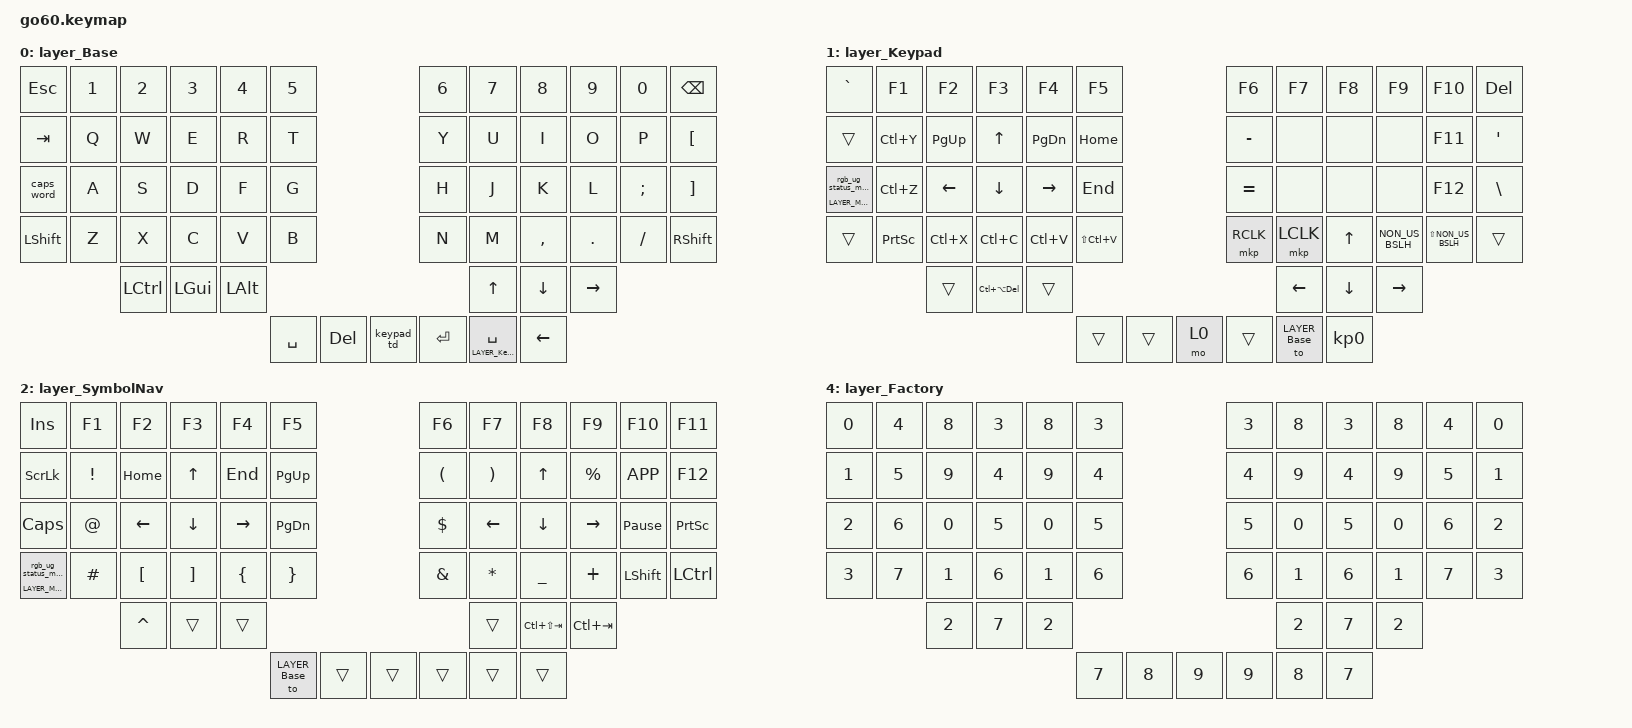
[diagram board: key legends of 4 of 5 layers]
/*
 * Copyright (c) 2020 The ZMK Contributors
 *
 * SPDX-License-Identifier: MIT
 */

#include <behaviors.dtsi>

#include <dt-bindings/zmk/bt.h>
#include <dt-bindings/zmk/ext_power.h>
#include <dt-bindings/zmk/keys.h>
#include <dt-bindings/zmk/outputs.h>
#include <dt-bindings/zmk/rgb.h>
#include <dt-bindings/zmk/input_transform.h>
#include <dt-bindings/zmk/pointing.h>

#include <input/processors.dtsi>
#include <zephyr/dt-bindings/input/input-event-codes.h>

// layers
#define LAYER_Base 0
#define LAYER_Keypad 1
#define LAYER_SymbolNav 2
#define LAYER_Magic 3
#define LAYER_Factory 4



/* Key positions */

#define POS_LH_C6R1 0
#define POS_LH_C5R1 1
#define POS_LH_C4R1 2
#define POS_LH_C3R1 3
#define POS_LH_C2R1 4
#define POS_LH_C1R1 5
#define POS_RH_C1R1 6
#define POS_RH_C2R1 7
#define POS_RH_C3R1 8
#define POS_RH_C4R1 9
#define POS_RH_C5R1 10
#define POS_RH_C6R1 11
#define POS_LH_C6R2 12
#define POS_LH_C5R2 13
#define POS_LH_C4R2 14
#define POS_LH_C3R2 15
#define POS_LH_C2R2 16
#define POS_LH_C1R2 17
#define POS_RH_C1R2 18
#define POS_RH_C2R2 19
#define POS_RH_C3R2 20
#define POS_RH_C4R2 21
#define POS_RH_C5R2 22
#define POS_RH_C6R2 23
#define POS_LH_C6R3 24
#define POS_LH_C5R3 25
#define POS_LH_C4R3 26
#define POS_LH_C3R3 27
#define POS_LH_C2R3 28
#define POS_LH_C1R3 29
#define POS_RH_C1R3 30
#define POS_RH_C2R3 31
#define POS_RH_C3R3 32
#define POS_RH_C4R3 33
#define POS_RH_C5R3 34
#define POS_RH_C6R3 35
#define POS_LH_C6R4 36
#define POS_LH_C5R4 37
#define POS_LH_C4R4 38
#define POS_LH_C3R4 39
#define POS_LH_C2R4 40
#define POS_LH_C1R4 41
#define POS_RH_C1R4 42
#define POS_RH_C2R4 43
#define POS_RH_C3R4 44
#define POS_RH_C4R4 45
#define POS_RH_C5R4 46
#define POS_RH_C6R4 47
#define POS_LH_C4R5 48
#define POS_LH_C3R5 49
#define POS_LH_C2R5 50
#define POS_RH_C2R5 51
#define POS_RH_C3R5 52
#define POS_RH_C4R5 53
#define POS_LH_T1 54
#define POS_LH_T2 55
#define POS_LH_T3 56
#define POS_RH_T3 57
#define POS_RH_T2 58
#define POS_RH_T1 59


#define LEFT_HAND_KEYS \
  POS_LH_C1R1 POS_LH_C2R1 POS_LH_C3R1 POS_LH_C4R1 POS_LH_C5R1 POS_LH_C6R1 \
  POS_LH_C1R2 POS_LH_C2R2 POS_LH_C3R2 POS_LH_C4R2 POS_LH_C5R2 POS_LH_C6R2 \
  POS_LH_C1R3 POS_LH_C2R3 POS_LH_C3R3 POS_LH_C4R3 POS_LH_C5R3 POS_LH_C6R3 \
  POS_LH_C1R4 POS_LH_C2R4 POS_LH_C3R4 POS_LH_C4R4 POS_LH_C5R4 POS_LH_C6R4 \
              POS_LH_C2R5 POS_LH_C3R5 POS_LH_C4R5

#define RIGHT_HAND_KEYS \
  POS_RH_C1R1 POS_RH_C2R1 POS_RH_C3R1 POS_RH_C4R1 POS_RH_C5R1 POS_RH_C6R1 \
  POS_RH_C1R2 POS_RH_C2R2 POS_RH_C3R2 POS_RH_C4R2 POS_RH_C5R2 POS_RH_C6R2 \
  POS_RH_C1R3 POS_RH_C2R3 POS_RH_C3R3 POS_RH_C4R3 POS_RH_C5R3 POS_RH_C6R3 \
  POS_RH_C1R4 POS_RH_C2R4 POS_RH_C3R4 POS_RH_C4R4 POS_RH_C5R4 POS_RH_C6R4 \
              POS_RH_C2R5 POS_RH_C3R5 POS_RH_C4R5

#define THUMB_KEYS \
  POS_LH_T1 POS_LH_T2 POS_LH_T3 \
  POS_RH_T1 POS_RH_T2 POS_RH_T3

/* Environment and metadata defines */
#define KB_TYPE_GLOVE_80 1
#define KB_TYPE_GO_60    2

#define KB_TYPE          KB_TYPE_GO_60
#define EDITOR_LAYOUT_OS 'W'
#define EDITOR_HOST_OS   'W'

/* To deal with the situation where there is no Lower layer, to keep &lower happy */
#ifndef LAYER_Lower
#define LAYER_Lower 0
#endif

/ {
    input_processors {
        zip_click_to_right_click_mapper: zip_click_to_right_click_mapper {
            compatible = "zmk,input-processor-code-mapper";
            #input-processor-cells = <0>;
            type = <INPUT_EV_KEY>;
            map = <INPUT_BTN_0 INPUT_BTN_1>;
        };
    };

    behaviors {
        magic: magic {
            compatible = "zmk,behavior-hold-tap";
            #binding-cells = <2>;
            flavor = "tap-preferred";
            tapping-term-ms = <200>;
            bindings = <&mo>, <&rgb_ug_status_macro>;
        };

        keypad_td: keypad_td {
            compatible = "zmk,behavior-tap-dance";
            #binding-cells = <0>;
            tapping-term-ms = <200>;
            bindings = <&mo LAYER_Keypad>, <&to LAYER_Keypad>;
        };

        symbol_nav_td: symbol_nav_td {
            compatible = "zmk,behavior-tap-dance";
            #binding-cells = <0>;
            tapping-term-ms = <200>;
            bindings = <&mo LAYER_SymbolNav>, <&to LAYER_SymbolNav>;
        };

        bt_0: bt_0 {
            compatible = "zmk,behavior-tap-dance";
            #binding-cells = <0>;
            tapping-term-ms = <200>;
            bindings = <&bt_select_0>, <&bt BT_DISC 0>;
        };
        bt_1: bt_1 {
            compatible = "zmk,behavior-tap-dance";
            #binding-cells = <0>;
            tapping-term-ms = <200>;
            bindings = <&bt_select_1>, <&bt BT_DISC 1>;
        };
        bt_2: bt_2 {
            compatible = "zmk,behavior-tap-dance";
            #binding-cells = <0>;
            tapping-term-ms = <200>;
            bindings = <&bt_select_2>, <&bt BT_DISC 2>;
        };
        bt_3: bt_3 {
            compatible = "zmk,behavior-tap-dance";
            #binding-cells = <0>;
            tapping-term-ms = <200>;
            bindings = <&bt_select_3>, <&bt BT_DISC 3>;
        };
    };

    macros {
        rgb_ug_status_macro: rgb_ug_status_macro {
            compatible = "zmk,behavior-macro";
            #binding-cells = <0>;
            bindings = <&rgb_ug RGB_STATUS>;
        };

        bt_select_0: bt_select_0 {
            compatible = "zmk,behavior-macro";
            #binding-cells = <0>;
            bindings
                = <&out OUT_BLE>,
                  <&bt BT_SEL 0>;
        };
        bt_select_1: bt_select_1 {
            compatible = "zmk,behavior-macro";
            #binding-cells = <0>;
            bindings
                = <&out OUT_BLE>,
                  <&bt BT_SEL 1>;
        };
        bt_select_2: bt_select_2 {
            compatible = "zmk,behavior-macro";
            #binding-cells = <0>;
            bindings
                = <&out OUT_BLE>,
                  <&bt BT_SEL 2>;
        };
        bt_select_3: bt_select_3 {
            compatible = "zmk,behavior-macro";
            #binding-cells = <0>;
            bindings
                = <&out OUT_BLE>,
                  <&bt BT_SEL 3>;
        };
    };

    keymap {
        compatible = "zmk,keymap";
        layer_Base {
            bindings = <
            &kp ESC  &kp N1     &kp N2   &kp N3    &kp N4  &kp N5                                                      &kp N6    &kp N7     &kp N8    &kp N9    &kp N0           &kp BSPC
              &kp TAB   &kp Q      &kp W    &kp E     &kp R   &kp T                                                       &kp Y     &kp U      &kp I     &kp O     &kp P            &kp LBKT
              &caps_word   &kp A      &kp S    &kp D     &kp F   &kp G                                                       &kp H     &kp J      &kp K     &kp L  &kp SEMI             &kp RBKT
 &kp LSHFT   &kp Z      &kp X    &kp C     &kp V   &kp B                                                       &kp N     &kp M  &kp COMMA   &kp DOT  &kp FSLH          &kp RSHFT
                               &kp LCTRL  &kp LGUI  &kp LALT                                                                      &kp UP   &kp DOWN  &kp RIGHT
                                                         &kp SPACE  &kp DEL  &keypad_td     &kp RET  &lt LAYER_Keypad SPACE  &kp LEFT
            >;
        };

        layer_Keypad {
            bindings = <
                &kp GRAVE     &kp F1     &kp F2     &kp F3     &kp F4         &kp F5                                                 &kp F6     &kp F7      &kp F8        &kp F9          &kp F10        &kp DEL
              &trans      &kp LC(Y)   &kp PG_UP     &kp UP    &kp PG_DN      &kp HOME                                              &kp MINUS  &none   &none  &none     &kp F11        &kp SQT
               &magic LAYER_Magic 0  &kp LC(Z)   &kp LEFT   &kp DOWN  &kp RIGHT      &kp END                                              &kp EQUAL         &none     &none            &none              &kp F12  &kp BSLH
 &trans  &kp PSCRN  &kp LC(X)  &kp LC(C)  &kp LC(V)  &kp LS(LC(V))                                              &mkp RCLK  &mkp LCLK   &kp UP  &kp NON_US_BSLH        &kp LS(NON_US_BSLH) &trans
                                      &trans     &kp LC(LA(DEL))     &trans                                                                        &kp LEFT  &kp DOWN      &kp RIGHT
                                                             &trans  &trans  &mo 0              &trans  &to LAYER_Base  &kp KP_N0
            >;
        };

        layer_SymbolNav {
            bindings = <
              &kp INS    &kp F1     &kp F2    &kp F3     &kp F4     &kp F5                                       &kp F6    &kp F7           &kp F8       &kp F9          &kp F10    &kp F11
             &kp SLCK  &kp EXCL   &kp HOME    &kp UP    &kp END  &kp PG_UP                                     &kp LPAR  &kp RPAR           &kp UP    &kp PRCNT        &kp K_APP    &kp F12
             &kp CAPS    &kp AT   &kp LEFT  &kp DOWN  &kp RIGHT  &kp PG_DN                                     &kp DLLR  &kp LEFT         &kp DOWN    &kp RIGHT  &kp PAUSE_BREAK  &kp PSCRN
 &magic LAYER_Magic 0  &kp HASH   &kp LBKT  &kp RBKT   &kp LBRC   &kp RBRC                                     &kp AMPS  &kp STAR        &kp UNDER     &kp PLUS        &kp LSHFT  &kp LCTRL
                                 &kp CARET    &trans     &trans                                                            &trans  &kp LC(LS(TAB))  &kp LC(TAB)
                                                            &to LAYER_Base  &trans  &trans       &trans  &trans  &trans
            >;
        };

        layer_Magic {
            bindings = <
  &bt BT_CLR     &kp C_BRI_DN     &kp C_BRI_UP       &kp C_PREV       &kp C_NEXT         &kp C_PP                                &kp C_MUTE  &kp C_VOL_DN  &kp C_VOL_UP   &none   &none    &bt BT_CLR_ALL
 &bootloader  &rgb_ug RGB_SPI  &rgb_ug RGB_SAI  &rgb_ug RGB_HUI  &rgb_ug RGB_BRI  &rgb_ug RGB_TOG                                     &bootloader   & 
none   &none   &none       &bootloader
  &magic LAYER_Magic 0  &rgb_ug RGB_SPD  &rgb_ug RGB_SAD  &rgb_ug RGB_HUD  &rgb_ug RGB_BRD  &rgb_ug RGB_EFF                                     &sys_reset    &none         &none   &none   &none        &sys_reset
       &none            &none            &bt_0            &bt_1            &bt_2            &bt_3                                     &none         &none         &none   &none   &none &to LAYER_Factory
                                  &out OUT_USB            &none            &none                                                                    &none         &none   &none
                                                                                            &none   &none   &none     &none   &none   &none
            >;
        };

        layer_Factory {
            bindings = <
 &kp N0  &kp N4  &kp N8  &kp N3  &kp N8  &kp N3                                                  &kp N3  &kp N8  &kp N3  &kp N8  &kp N4  &kp N0
 &kp N1  &kp N5  &kp N9  &kp N4  &kp N9  &kp N4                                                  &kp N4  &kp N9  &kp N4  &kp N9  &kp N5  &kp N1
 &kp N2  &kp N6  &kp N0  &kp N5  &kp N0  &kp N5                                                  &kp N5  &kp N0  &kp N5  &kp N0  &kp N6  &kp N2
 &kp N3  &kp N7  &kp N1  &kp N6  &kp N1  &kp N6                                                  &kp N6  &kp N1  &kp N6  &kp N1  &kp N7  &kp N3
                 &kp N2  &kp N7  &kp N2                                                                  &kp N2  &kp N7  &kp N2
                                                 &kp N7  &kp N8  &kp N9  &kp N9  &kp N8  &kp N7
            >;
        };
    };
};

#if __has_include(<dt-bindings/zmk/rgb_colors.h>)
  //
  // Color definitions with conflict guard to prevent
  // accidental redefinition of common abbreviations.
  //
  #if defined(RED) || defined(RED_RGB) || \
      defined(COR) || defined(COR_RGB) || \
      defined(ORN) || defined(ORN_RGB) || \
      defined(GDN) || defined(GDN_RGB) || \
      defined(GOL) || defined(GOL_RGB) || \
      defined(YLW) || defined(YLW_RGB) || \
      defined(CHU) || defined(CHU_RGB) || \
      defined(GRN) || defined(GRN_RGB) || \
      defined(SPG) || defined(SPG_RGB) || \
      defined(CYN) || defined(CYN_RGB) || \
      defined(AZU) || defined(AZU_RGB) || \
      defined(TEA) || defined(TEA_RGB) || \
      defined(TUR) || defined(TUR_RGB) || \
      defined(BLU) || defined(BLU_RGB) || \
      defined(PUR) || defined(PUR_RGB) || \
      defined(MAJ) || defined(MAJ_RGB) || \
      defined(PNK) || defined(PNK_RGB) || \
      defined(WHT) || defined(WHT_RGB) || \
      defined(BLK) || defined(BLK_RGB) || \
      defined(___) || \
      defined(DUG) || defined(DUG_RGB) || \
      defined(LAC) || defined(LAC_RGB) || \
      defined(BSL) || defined(BNL) || defined(BCL) || \
      defined(SSL) || defined(SNL) || defined(SCL) || \
      defined(FST) || defined(WRP) || defined(SLO)
  #error "Naming conflict: 3-letter color abbreviation already defined!"
  #endif

  //
  // Color definitions
  //
  #define RED_RGB 0xFF0000
  #define COR_RGB 0xFF7C4D
  #define ORN_RGB 0xFF8000
  #define GDN_RGB 0xD9A521
  #define GOL_RGB 0xFFD900
  #define YLW_RGB 0xFFFF00
  #define CHU_RGB 0x80FF00
  #define GRN_RGB 0x00FF00
  #define SPG_RGB 0x00FF80
  #define CYN_RGB 0x00FFFF
  #define AZU_RGB 0x99F5FF
  #define TEA_RGB 0x008080
  #define TUR_RGB 0x476E6A
  #define BLU_RGB 0x0000FF
  #define PUR_RGB 0x7A00FF
  #define MAJ_RGB 0xFF00FF
  #define PNK_RGB 0xFF80BF
  #define WHT_RGB 0xFFFFFF
  #define BLK_RGB 0x000000
  #define DUG_RGB 0x00FF68
  #define LAC_RGB 0x6B1FCE

  //
  // Short color names
  //
  #define RED &ug RED_RGB
  #define COR &ug COR_RGB
  #define ORN &ug ORN_RGB
  #define GDN &ug GDN_RGB
  #define GOL &ug GOL_RGB
  #define YLW &ug YLW_RGB
  #define CHU &ug CHU_RGB
  #define GRN &ug GRN_RGB
  #define SPG &ug SPG_RGB
  #define CYN &ug CYN_RGB
  #define AZU &ug AZU_RGB
  #define TEA &ug TEA_RGB
  #define TUR &ug TUR_RGB
  #define BLU &ug BLU_RGB
  #define PUR &ug PUR_RGB
  #define MAJ &ug MAJ_RGB
  #define PNK &ug PNK_RGB
  #define WHT &ug WHT_RGB
  #define ___ &ug BLK_RGB
  #define DUG &ug DUG_RGB
  #define LAC &ug LAC_RGB

  //
  // Lock-key underglow for Base layer
  //
  #define BSL &ug_sl BLK_RGB RED_RGB
  #define BNL &ug_nl BLK_RGB RED_RGB
  #define BCL &ug_cl BLK_RGB RED_RGB

  //
  // Mouse speed indicators
  //
  #define FST GOL
  #define WRP CHU
  #define SLO COR

  // ==== PER-KEY RGB LAYERS BEGIN ====
  / {
    underglow-layer {
      compatible = "zmk,underglow-layer";

      #ifdef LAYER_Base
      Base {
        bindings = <
          ORN YLW YLW YLW YLW YLW                                     YLW YLW YLW YLW YLW ORN
          ORN CYN CYN CYN CYN CYN                                     CYN CYN CYN CYN CYN CYN
          ORN CYN CYN CYN CYN CYN                                     CYN CYN CYN CYN CYN CYN
          WHT CYN CYN CYN CYN CYN                                     CYN CYN CYN CYN CYN WHT
                  WHT PUR WHT                                             ORN ORN ORN 
                                       GRN RED GOL     RED GOL ORN 
        >;
        layer-id = <LAYER_Base>;
        fade-delay = <30>;
      };
      #endif

      #ifdef LAYER_Keypad
      Keypad {
        bindings = <
          RED ORN ORN ORN ORN GRN                                     ORN ORN ORN GRN ORN WHT 
          RED RED RED YLW RED RED                                     CYN ___ ___ ___ ORN CYN 
          WHT RED YLW YLW YLW RED                                     CYN ___ ___ ___ ORN CYN
          WHT RED RED RED RED CYN                                     GRN GRN YLW CYN CYN WHT
                  WHT BLU WHT                                             YLW YLW YLW  
                                       GRN RED GOL     RED GOL WHT 
        >;
        layer-id = <LAYER_Keypad>;
        fade-delay = <15>;
      };
      #endif

    }; // end underglow-layer
  };   // end /

  /* ============================================================
   * BEHAVIORS
   * ============================================================
   */
  / {
    behaviors {

      /*
       * uglowbat
       * ----------
       * Battery-aware underglow behavior.
       */
      uglowbat: uglowbat {
        compatible = "zmk,behavior-underglow-battery";
        threshold = <30>;
        #binding-cells = <2>;
      };
    }; // end behaviors
   
  };   // end /

  // ==== PER-KEY RGB LAYERS END ====

  // Cleanup
  #undef RED
  #undef RED_RGB
  #undef COR
  #undef COR_RGB
  #undef ORN
  #undef ORN_RGB
  #undef GDN
  #undef GDN_RGB
  #undef GOL
  #undef GOL_RGB
  #undef YLW
  #undef YLW_RGB
  #undef CHU
  #undef CHU_RGB
  #undef GRN
  #undef GRN_RGB
  #undef SPG
  #undef SPG_RGB
  #undef CYN
  #undef CYN_RGB
  #undef AZU
  #undef AZU_RGB
  #undef TEA
  #undef TEA_RGB
  #undef TUR
  #undef TUR_RGB
  #undef BLU
  #undef BLU_RGB
  #undef PUR
  #undef PUR_RGB
  #undef MAJ
  #undef MAJ_RGB
  #undef PNK
  #undef PNK_RGB
  #undef WHT
  #undef WHT_RGB
  #undef BLK
  #undef BLK_RGB
  #undef ___
  #undef DUG
  #undef DUG_RGB
  #undef LAC
  #undef LAC_RGB

  #undef BSL
  #undef BNL
  #undef BCL

  #undef SSL
  #undef SNL
  #undef SCL

  #undef FST
  #undef WRP
  #undef SLO

#endif

/* Input Listeners */
&cirque_rh_listener {
    input-processors = <&zip_xy_scaler 11 12>, <&zip_xy_transform INPUT_TRANSFORM_Y_INVERT>, <&zip_xy_to_scroll_mapper>, <&zip_click_to_right_click_mapper>;
    layer_SymbolNav {
        layers = <LAYER_SymbolNav>;
        input-processors = <&zip_xy_scaler 9 1>;
    };
};

&cirque_lh_listener {
    input-processors = <&zip_xy_scaler 3 1>;
    layer_Factory {
        layers = <LAYER_Factory>;
        input-processors = <&zip_xy_scaler 3 1>;
    };
};
